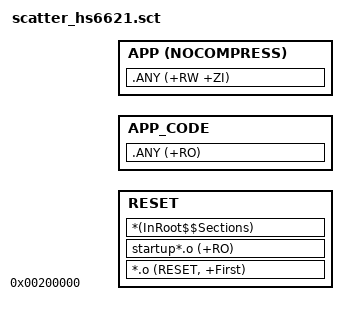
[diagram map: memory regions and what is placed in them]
#! armcc -E
; ***************************************************************
; *** Scatter-Loading Description File generated by Huntersun ***
; ***************************************************************

RAM_LOAD 0x00200000 0x00040000
{
    RESET 0x00200000
    {
        *.o (RESET, +First)
        startup*.o (+RO)
        *(InRoot$$Sections)
    }

    APP_CODE +0
    {
        .ANY (+RO)
    }

    APP 0x20000000 + ImageLimit(APP_CODE) - 0x00200000 NOCOMPRESS
    {
        .ANY (+RW +ZI)
    }
}

ScatterAssert(ImageLimit(RESET) < 0x00202000)
ScatterAssert(ImageLimit(APP)   < 0x20060880)

